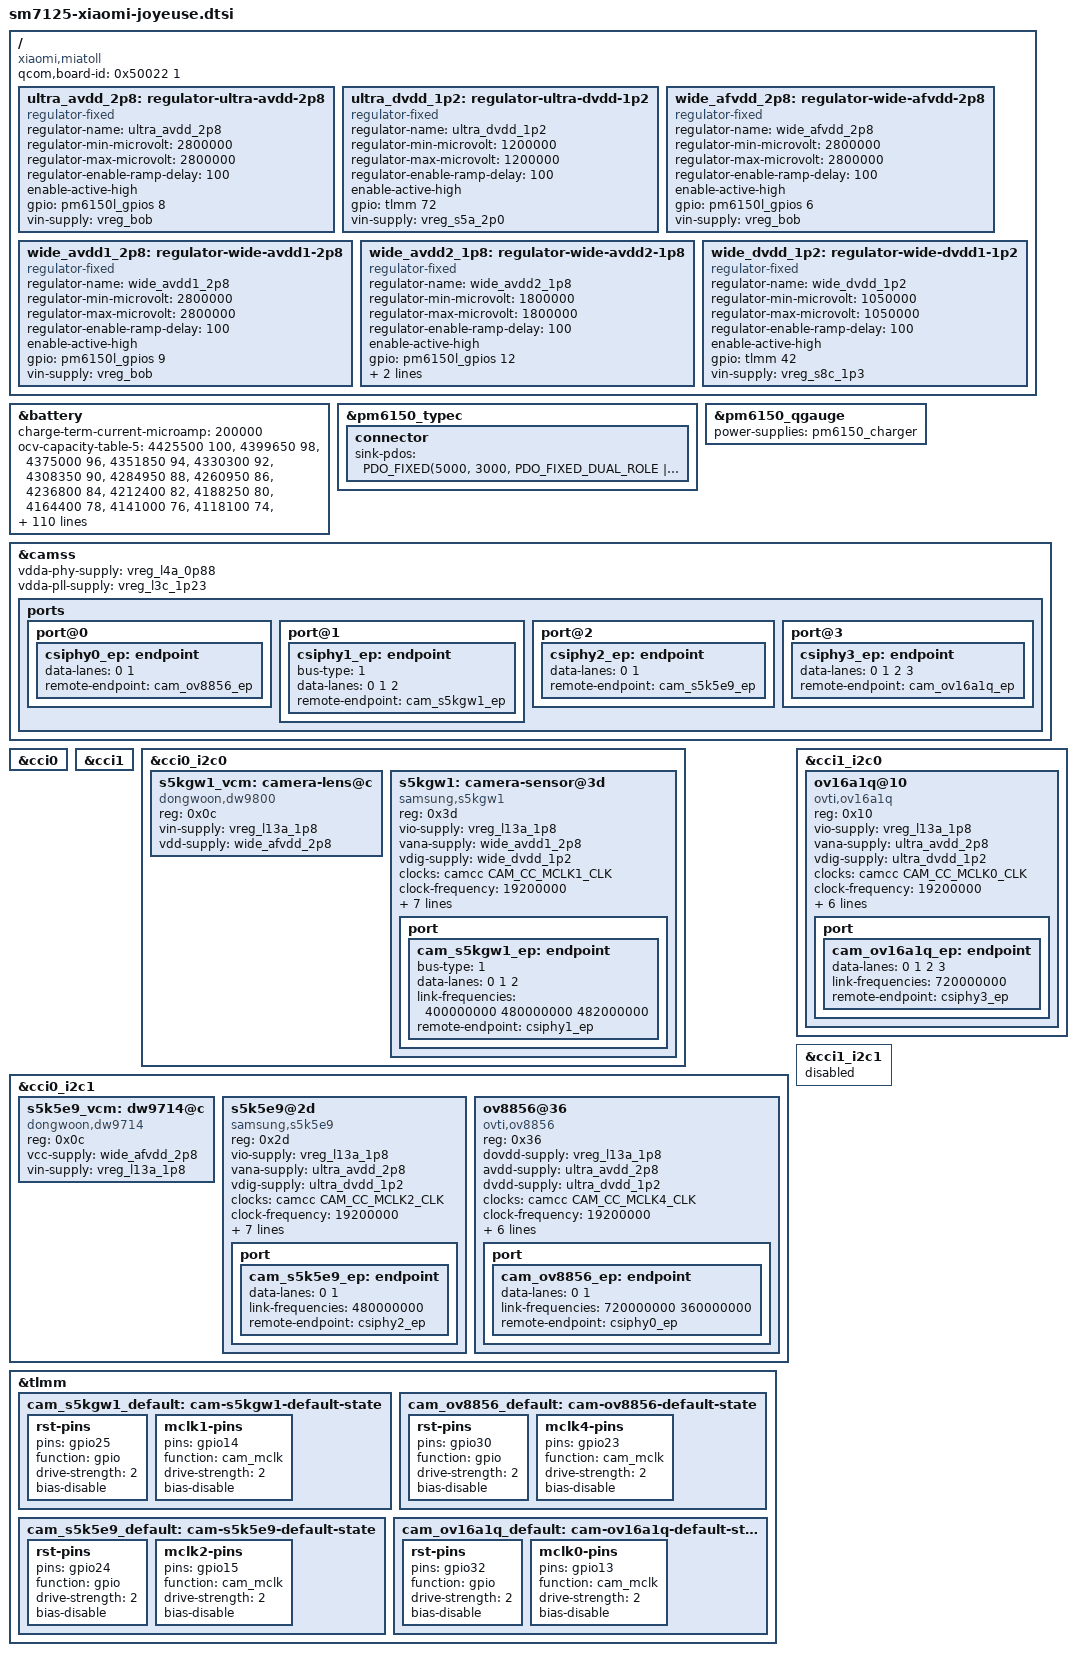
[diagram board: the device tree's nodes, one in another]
// SPDX-License-Identifier: GPL-2.0
/*
 * Copyright (c) 2021, The Linux Foundation. All rights reserved.
 * Copyright (C) 2025 Vitalii Skorkin <nikroksm@mail.ru>
 */

/dts-v1/;

#include "sm7125-xiaomi-common.dtsi"

&battery {
	/* Normal SMB5 termination; distinct from QGauge's 350 mA threshold. */
	charge-term-current-microamp = <200000>;

	/*
	 * EXPERIMENTAL nominal discharge profile: the average of the vendor
	 * NVT and Sunwoda profiles at identical SOC coordinates. It does not
	 * identify the fitted cell and its 100 % point (4.4255 V) is above
	 * what this phone reaches at charge termination.
	 */
	ocv-capacity-table-5 = <4425500 100>,
		<4399650 98>,
		<4375000 96>,
		<4351850 94>,
		<4330300 92>,
		<4308350 90>,
		<4284950 88>,
		<4260950 86>,
		<4236800 84>,
		<4212400 82>,
		<4188250 80>,
		<4164400 78>,
		<4141000 76>,
		<4118100 74>,
		<4095750 72>,
		<4074100 70>,
		<4053150 68>,
		<4032900 66>,
		<4013950 64>,
		<3996250 62>,
		<3977150 60>,
		<3954100 58>,
		<3930150 56>,
		<3909450 54>,
		<3890800 52>,
		<3875050 50>,
		<3862100 48>,
		<3850750 46>,
		<3840250 44>,
		<3830500 42>,
		<3821600 40>,
		<3813700 38>,
		<3806150 36>,
		<3798550 34>,
		<3790900 32>,
		<3782000 30>,
		<3770500 28>,
		<3758400 26>,
		<3748200 24>,
		<3739100 22>,
		<3729950 20>,
		<3720500 18>,
		<3709300 16>,
		<3694550 14>,
		<3683500 12>,
		<3678950 10>,
		<3677700 9>,
		<3676150 8>,
		<3673100 7>,
		<3662550 6>,
		<3628500 5>,
		<3577750 4>,
		<3510650 3>,
		<3417150 2>,
		<3277500 1>,
		<2812700 0>;
	ocv-capacity-table-4 = <4427500 100>,
		<4401600 98>,
		<4376900 96>,
		<4353750 94>,
		<4332100 92>,
		<4310100 90>,
		<4286500 88>,
		<4262350 86>,
		<4238100 84>,
		<4213650 82>,
		<4189450 80>,
		<4165600 78>,
		<4142100 76>,
		<4119100 74>,
		<4096750 72>,
		<4075100 70>,
		<4054200 68>,
		<4034150 66>,
		<4015050 64>,
		<3997150 62>,
		<3977750 60>,
		<3954300 58>,
		<3929900 56>,
		<3908950 54>,
		<3890200 52>,
		<3874450 50>,
		<3861500 48>,
		<3850300 46>,
		<3839850 44>,
		<3830250 42>,
		<3821600 40>,
		<3813800 38>,
		<3806450 36>,
		<3799150 34>,
		<3791900 32>,
		<3783700 30>,
		<3773850 28>,
		<3763350 26>,
		<3753700 24>,
		<3744550 22>,
		<3735300 20>,
		<3725850 18>,
		<3714700 16>,
		<3700300 14>,
		<3688950 12>,
		<3684000 10>,
		<3682900 9>,
		<3681400 8>,
		<3678500 7>,
		<3670000 6>,
		<3638400 5>,
		<3588400 4>,
		<3522450 3>,
		<3429150 2>,
		<3287850 1>,
		<2819200 0>;
	ocv-capacity-table-3 = <4431500 100>,
		<4405200 98>,
		<4380100 96>,
		<4356600 94>,
		<4334700 92>,
		<4312450 90>,
		<4288600 88>,
		<4264150 86>,
		<4239750 84>,
		<4215300 82>,
		<4191100 80>,
		<4167100 78>,
		<4143500 76>,
		<4120450 74>,
		<4098050 72>,
		<4076350 70>,
		<4055250 68>,
		<4034850 66>,
		<4015550 64>,
		<3997500 62>,
		<3977550 60>,
		<3952750 58>,
		<3927000 56>,
		<3905900 54>,
		<3887850 52>,
		<3872550 50>,
		<3859450 48>,
		<3848000 46>,
		<3837350 44>,
		<3827500 42>,
		<3818450 40>,
		<3810250 38>,
		<3802650 36>,
		<3795500 34>,
		<3788650 32>,
		<3781650 30>,
		<3774300 28>,
		<3766500 26>,
		<3758350 24>,
		<3749900 22>,
		<3740950 20>,
		<3731000 18>,
		<3719000 16>,
		<3704700 14>,
		<3692300 12>,
		<3686550 10>,
		<3684600 9>,
		<3682650 8>,
		<3679000 7>,
		<3670400 6>,
		<3641050 5>,
		<3589700 4>,
		<3522550 3>,
		<3428100 2>,
		<3276200 1>,
		<2772650 0>;
	ocv-capacity-table-2 = <4432500 100>,
		<4404150 98>,
		<4377750 96>,
		<4353650 94>,
		<4332050 92>,
		<4309900 90>,
		<4285750 88>,
		<4260800 86>,
		<4236000 84>,
		<4211100 82>,
		<4186550 80>,
		<4162350 78>,
		<4138650 76>,
		<4115600 74>,
		<4093300 72>,
		<4071950 70>,
		<4052450 68>,
		<4033350 66>,
		<4012600 64>,
		<3989650 62>,
		<3966050 60>,
		<3941350 58>,
		<3917450 56>,
		<3897700 54>,
		<3880400 52>,
		<3864900 50>,
		<3851000 48>,
		<3838450 46>,
		<3826750 44>,
		<3815750 42>,
		<3806100 40>,
		<3797350 38>,
		<3789850 36>,
		<3784650 34>,
		<3781050 32>,
		<3777300 30>,
		<3773350 28>,
		<3769000 26>,
		<3763000 24>,
		<3755050 22>,
		<3745150 20>,
		<3732450 18>,
		<3717700 16>,
		<3701500 14>,
		<3687450 12>,
		<3678350 10>,
		<3674500 9>,
		<3670400 8>,
		<3664800 7>,
		<3654650 6>,
		<3630450 5>,
		<3585350 4>,
		<3521000 3>,
		<3426650 2>,
		<3274600 1>,
		<2829250 0>;
	ocv-capacity-table-1 = <4434500 100>,
		<4402300 98>,
		<4373100 96>,
		<4347500 94>,
		<4325450 92>,
		<4303200 90>,
		<4278950 88>,
		<4253850 86>,
		<4228450 84>,
		<4202700 82>,
		<4177250 80>,
		<4151450 78>,
		<4126750 76>,
		<4107300 74>,
		<4092550 72>,
		<4075850 70>,
		<4050150 68>,
		<4019100 66>,
		<3992500 64>,
		<3969100 62>,
		<3946700 60>,
		<3924150 58>,
		<3902400 56>,
		<3882900 54>,
		<3865050 52>,
		<3848600 50>,
		<3832050 48>,
		<3817300 46>,
		<3808650 44>,
		<3803300 42>,
		<3798800 40>,
		<3794200 38>,
		<3789800 36>,
		<3785200 34>,
		<3780500 32>,
		<3775450 30>,
		<3770000 28>,
		<3764050 26>,
		<3757000 24>,
		<3748850 22>,
		<3739450 20>,
		<3728150 18>,
		<3715200 16>,
		<3701050 14>,
		<3687900 12>,
		<3678050 10>,
		<3674200 9>,
		<3670500 8>,
		<3666600 7>,
		<3660050 6>,
		<3645450 5>,
		<3609450 4>,
		<3546050 3>,
		<3454600 2>,
		<3318850 1>,
		<2974850 0>;
	ocv-capacity-table-0 = <4437250 100>,
		<4398200 98>,
		<4363550 96>,
		<4334400 94>,
		<4310250 92>,
		<4286450 90>,
		<4259950 88>,
		<4233200 86>,
		<4209100 84>,
		<4187200 82>,
		<4166300 80>,
		<4145800 78>,
		<4125150 76>,
		<4103150 74>,
		<4079450 72>,
		<4053200 70>,
		<4020800 68>,
		<3984250 66>,
		<3955450 64>,
		<3933500 62>,
		<3913250 60>,
		<3890800 58>,
		<3868700 56>,
		<3852900 54>,
		<3841500 52>,
		<3832200 50>,
		<3824500 48>,
		<3817950 46>,
		<3811850 44>,
		<3806150 42>,
		<3800650 40>,
		<3794800 38>,
		<3788900 36>,
		<3782650 34>,
		<3776200 32>,
		<3769350 30>,
		<3762050 28>,
		<3754300 26>,
		<3746100 24>,
		<3737350 22>,
		<3728400 20>,
		<3719650 18>,
		<3711100 16>,
		<3703400 14>,
		<3696150 12>,
		<3688450 10>,
		<3683900 9>,
		<3678350 8>,
		<3672100 7>,
		<3663350 6>,
		<3648600 5>,
		<3620750 4>,
		<3575100 3>,
		<3500450 2>,
		<3382150 1>,
		<3124750 0>;
	ocv-capacity-celsius = <(-10) 0 10 25 40 50>;
};

&pm6150_typec {
	connector {
		/* Higher voltages require coordinated SMB5 input configuration. */
		sink-pdos = <PDO_FIXED(5000, 3000, PDO_FIXED_DUAL_ROLE |
				      PDO_FIXED_USB_COMM | PDO_FIXED_DATA_SWAP)>;
	};
};

&pm6150_qgauge {
	power-supplies = <&pm6150_charger>;
};

/ {
	compatible = "xiaomi,miatoll", "xiaomi,joyeuse", "qcom,sm7125";
	/* required for bootloader to select correct board */
	qcom,board-id = <0x50022 1>;

	ultra_avdd_2p8: regulator-ultra-avdd-2p8 {
		compatible = "regulator-fixed";
		regulator-name = "ultra_avdd_2p8";
		regulator-min-microvolt = <2800000>;
		regulator-max-microvolt = <2800000>;
		regulator-enable-ramp-delay = <100>;
		enable-active-high;
		gpio = <&pm6150l_gpios 8 0>;
		vin-supply = <&vreg_bob>;
	};

	ultra_dvdd_1p2: regulator-ultra-dvdd-1p2 {
		compatible = "regulator-fixed";
		regulator-name = "ultra_dvdd_1p2";
		regulator-min-microvolt = <1200000>;
		regulator-max-microvolt = <1200000>;
		regulator-enable-ramp-delay = <100>;
		enable-active-high;
		gpio = <&tlmm 72 0>;
		vin-supply = <&vreg_s5a_2p0>;
	};

	wide_afvdd_2p8: regulator-wide-afvdd-2p8 {
		compatible = "regulator-fixed";
		regulator-name = "wide_afvdd_2p8";
		regulator-min-microvolt = <2800000>;
		regulator-max-microvolt = <2800000>;
		regulator-enable-ramp-delay = <100>;
		enable-active-high;
		gpio = <&pm6150l_gpios 6 0>;
		vin-supply = <&vreg_bob>;
	};

	wide_avdd1_2p8: regulator-wide-avdd1-2p8 {
		compatible = "regulator-fixed";
		regulator-name = "wide_avdd1_2p8";
		regulator-min-microvolt = <2800000>;
		regulator-max-microvolt = <2800000>;
		regulator-enable-ramp-delay = <100>;
		enable-active-high;
		gpio = <&pm6150l_gpios 9 0>;
		vin-supply = <&vreg_bob>;
	};

	wide_avdd2_1p8: regulator-wide-avdd2-1p8 {
		compatible = "regulator-fixed";
		regulator-name = "wide_avdd2_1p8";
		regulator-min-microvolt = <1800000>;
		regulator-max-microvolt = <1800000>;
		regulator-enable-ramp-delay = <100>;
		enable-active-high;
		gpio = <&pm6150l_gpios 12 0>;
		vin-supply = <&vreg_l13a_1p8>;
		regulator-always-on;
	};

	wide_dvdd_1p2: regulator-wide-dvdd1-1p2 {
		compatible = "regulator-fixed";
		regulator-name = "wide_dvdd_1p2";
		regulator-min-microvolt = <1050000>;
		regulator-max-microvolt = <1050000>;
		regulator-enable-ramp-delay = <100>;
		enable-active-high;
		gpio = <&tlmm 42 0>;
		vin-supply = <&vreg_s8c_1p3>;
	};
};

&camss {
	vdda-phy-supply = <&vreg_l4a_0p88>;
	vdda-pll-supply = <&vreg_l3c_1p23>;

	status = "okay";

	ports {
		#address-cells = <1>;
		#size-cells = <0>;

		port@0 {
			csiphy0_ep: endpoint {
				data-lanes = <0 1>;
				remote-endpoint = <&cam_ov8856_ep>;
			};
		};

		port@1 {
			csiphy1_ep: endpoint {
				bus-type = <1>;
				data-lanes = <0 1 2>;
				remote-endpoint = <&cam_s5kgw1_ep>;
			};
		};

		port@2 {
			csiphy2_ep: endpoint {
				data-lanes = <0 1>;
				remote-endpoint = <&cam_s5k5e9_ep>;
			};
		};

		port@3 {
			csiphy3_ep: endpoint {
				data-lanes = <0 1 2 3>;
				remote-endpoint = <&cam_ov16a1q_ep>;
			};
		};
	};
};

&cci0 {
	status = "okay";
};

&cci1 {
	status = "okay";
};

&cci0_i2c0 {
	status = "okay";

	/* S5KGW1 EEPROM @ 0x51 */

	s5kgw1_vcm: camera-lens@c {
		compatible = "dongwoon,dw9800";
		reg = <0x0c>;

		vin-supply = <&vreg_l13a_1p8>;
		vdd-supply = <&wide_afvdd_2p8>;
	};

	s5kgw1: camera-sensor@3d {
		compatible = "samsung,s5kgw1";
		reg = <0x3d>;

		vio-supply = <&vreg_l13a_1p8>;
		vana-supply = <&wide_avdd1_2p8>;
		vdig-supply = <&wide_dvdd_1p2>;

		clocks = <&camcc CAM_CC_MCLK1_CLK>;
		clock-names = "xvclk";
		clock-frequency = <19200000>;
		assigned-clocks = <&camcc CAM_CC_MCLK1_CLK>;
		assigned-clock-rates = <19200000>;

		reset-gpios = <&tlmm 25 GPIO_ACTIVE_HIGH>;
		pinctrl-names = "default";
		pinctrl-0 = <&cam_s5kgw1_default>;

		orientation = <1>;
		rotation = <90>; /* mounted 180 deg from the other rear sensors */

		lens-focus = <&s5kgw1_vcm>;

		port {
			cam_s5kgw1_ep: endpoint {
				bus-type = <1>;
				data-lanes = <0 1 2>;
				link-frequencies = /bits/ 64 <400000000 480000000 482000000>;
				remote-endpoint = <&csiphy1_ep>;
			};
		};
	};
};

&cci0_i2c1 {
	status = "okay";

	/* S5K5E9 EEPROM @ 0x51 */

	s5k5e9_vcm: dw9714@c {
		compatible = "dongwoon,dw9714";
		reg = <0x0c>;
		vcc-supply = <&wide_afvdd_2p8>;
		vin-supply = <&vreg_l13a_1p8>;
	};

	s5k5e9@2d {
		compatible = "samsung,s5k5e9";
		reg = <0x2d>;

		vio-supply = <&vreg_l13a_1p8>;
		vana-supply = <&ultra_avdd_2p8>;
		vdig-supply = <&ultra_dvdd_1p2>;

		clocks = <&camcc CAM_CC_MCLK2_CLK>;
		clock-names = "xvclk";
		clock-frequency = <19200000>;
		assigned-clocks = <&camcc CAM_CC_MCLK2_CLK>;
		assigned-clock-rates = <19200000>;

		reset-gpios = <&tlmm 24 GPIO_ACTIVE_HIGH>;
		pinctrl-names = "default";
		pinctrl-0 = <&cam_s5k5e9_default>;

		orientation = <1>;
		rotation = <270>;

		lens-focus = <&s5k5e9_vcm>;

		port {
			cam_s5k5e9_ep: endpoint {
				data-lanes = <0 1>;
				link-frequencies = /bits/ 64 <480000000>;
				remote-endpoint = <&csiphy2_ep>;
			};
		};
	};

	ov8856@36 {
		compatible = "ovti,ov8856";
		reg = <0x36>;

		dovdd-supply = <&vreg_l13a_1p8>;
		avdd-supply = <&ultra_avdd_2p8>;
		dvdd-supply = <&ultra_dvdd_1p2>;

		clocks = <&camcc CAM_CC_MCLK4_CLK>;
		clock-names = "xvclk";
		clock-frequency = <19200000>;
		assigned-clocks = <&camcc CAM_CC_MCLK4_CLK>;
		assigned-clock-rates = <19200000>;

		reset-gpios = <&tlmm 30 GPIO_ACTIVE_LOW>;
		pinctrl-names = "default";
		pinctrl-0 = <&cam_ov8856_default>;

		orientation = <1>;
		rotation = <270>;

		port {
			cam_ov8856_ep: endpoint {
				data-lanes = <0 1>;
				link-frequencies = /bits/ 64
					<720000000 360000000>;
				remote-endpoint = <&csiphy0_ep>;
			};
		};
	};
};

&cci1_i2c0 {
	status = "okay";

	/* OV2180 EEPROM @ 0x54 */
	/* OV2180 @ 0x36 */

	/* OV16A1Q EEPROM @ 0x50 */

	ov16a1q@10 {
		compatible = "ovti,ov16a1q";
		reg = <0x10>;

		vio-supply = <&vreg_l13a_1p8>;
		vana-supply = <&ultra_avdd_2p8>;
		vdig-supply = <&ultra_dvdd_1p2>;

		clocks = <&camcc CAM_CC_MCLK0_CLK>;
		clock-names = "xvclk";
		clock-frequency = <19200000>;
		assigned-clocks = <&camcc CAM_CC_MCLK0_CLK>;
		assigned-clock-rates = <19200000>;

		reset-gpios = <&tlmm 32 GPIO_ACTIVE_HIGH>;
		pinctrl-names = "default";
		pinctrl-0 = <&cam_ov16a1q_default>;

		orientation = <0>;
		rotation = <90>;

		port {
			cam_ov16a1q_ep: endpoint {
				data-lanes = <0 1 2 3>;
				link-frequencies = /bits/ 64 <720000000>;
				remote-endpoint = <&csiphy3_ep>;
			};
		};
	};
};

&cci1_i2c1 {
	status = "disabled";
};

&tlmm {
	cam_s5kgw1_default: cam-s5kgw1-default-state {
		rst-pins {
			pins = "gpio25";
			function = "gpio";
			drive-strength = <2>;
			bias-disable;
		};

		mclk1-pins {
			pins = "gpio14";
			function = "cam_mclk";
			drive-strength = <2>;
			bias-disable;
		};
	};

	cam_ov8856_default: cam-ov8856-default-state {
		rst-pins {
			pins = "gpio30";
			function = "gpio";
			drive-strength = <2>;
			bias-disable;
		};

		mclk4-pins {
			pins = "gpio23";
			function = "cam_mclk";
			drive-strength = <2>;
			bias-disable;
		};
	};

	cam_s5k5e9_default: cam-s5k5e9-default-state {
		rst-pins {
			pins = "gpio24";
			function = "gpio";
			drive-strength = <2>;
			bias-disable;
		};

		mclk2-pins {
			pins = "gpio15";
			function = "cam_mclk";
			drive-strength = <2>;
			bias-disable;
		};
	};

	cam_ov16a1q_default: cam-ov16a1q-default-state {
		rst-pins {
			pins = "gpio32";
			function = "gpio";
			drive-strength = <2>;
			bias-disable;
		};

		mclk0-pins {
			pins = "gpio13";
			function = "cam_mclk";
			drive-strength = <2>;
			bias-disable;
		};
	};
};
